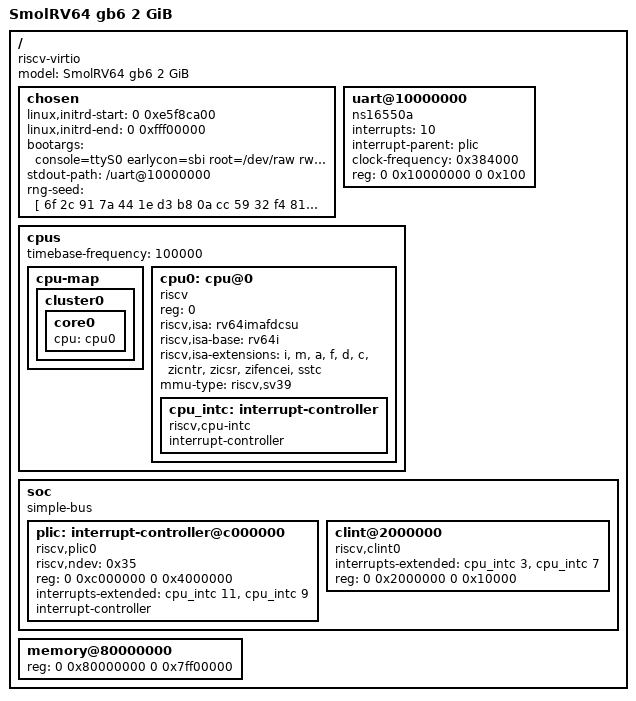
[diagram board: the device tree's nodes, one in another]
/dts-v1/;

/ {
	#address-cells = <2>;
	#size-cells = <2>;
	compatible = "riscv-virtio";
	model = "SmolRV64 gb6 2 GiB";

	chosen {
		linux,initrd-start = <0 0xe5f8ca00>;
		linux,initrd-end   = <0 0xfff00000>;
		bootargs = "console=ttyS0 earlycon=sbi root=/dev/raw rw ignore_loglevel random.trust_bootloader=on";
		stdout-path = "/uart@10000000";

                /* Development-only static seed: replace with per-boot random bytes later. */
                rng-seed = [
                        6f 2c 91 7a 44 1e d3 b8
                        0a cc 59 32 f4 81 25 9d
                        e7 10 ba 6c 38 5f 02 c1
                        93 d4 76 af 20 8b ee 41
                        15 62 9a cd 57 03 b4 f8
                        80 2d 11 6e a9 4c 73 05
                        dc 37 f1 98 24 bb 60 0f
                        4a e2 7d 36 c5 19 8c a0
                ];
	};

	uart@10000000 {
		interrupts = <10>;
		interrupt-parent = <&plic>;
		clock-frequency = <0x384000>;
		reg = <0 0x10000000 0 0x100>;
		compatible = "ns16550a";
	};

	cpus {
		#address-cells = <1>;
		#size-cells = <0>;
		timebase-frequency = <100000>; /* 100 kHz */

		cpu-map {

			cluster0 {

				core0 {
					cpu = <&cpu0>;
				};
			};
		};

		cpu0: cpu@0 {
			device_type = "cpu";
			reg = <0>;
			status = "okay";
			compatible = "riscv";
			riscv,isa = "rv64imafdcsu";
			riscv,isa-base = "rv64i";
			riscv,isa-extensions = "i", "m", "a", "f", "d", "c",
				"zicntr", "zicsr", "zifencei", "sstc";
			mmu-type = "riscv,sv39";

			cpu_intc: interrupt-controller {
				#interrupt-cells = <1>;
				interrupt-controller;
				compatible = "riscv,cpu-intc";
			};
		};
	};

	soc {
		#address-cells = <2>;
		#size-cells = <2>;
		compatible = "simple-bus";
		ranges;

		plic: interrupt-controller@c000000 {
			riscv,ndev = <0x35>;
			reg = <0 0xc000000 0 0x4000000>;
			interrupts-extended = <&cpu_intc 11 &cpu_intc 9>;
			interrupt-controller;
			compatible = "riscv,plic0";
			#interrupt-cells = <1>;
			#address-cells = <0>;
		};

		clint@2000000 {
			interrupts-extended = <&cpu_intc 3 &cpu_intc 7>;
			reg = <0 0x2000000 0 0x10000>;
			compatible = "riscv,clint0";
		};
	};

	memory@80000000 {
		device_type = "memory";
		reg = <0 0x80000000 0 0x7ff00000>; // 2047 MiB
		// initrd (0x96270e00..0x9ff00000) and DTB (0x9ff00000) sit inside
		// this window now; the kernel reserves both (FDT via a1, initrd via
		// the chosen node), so they are not clobbered.
	};
};
